# STM32F446MCY6 register map
File version: 1.0
Registers are 32-bit, access not given, reset 0x0 unless marked. A register's access mark holds for its fields unless they carry their own. Offsets are from the block's base; [hi:lo] are bit positions; {n}, {i} and the like mark numbered series; 'fields as' and 'values as' point back to an identical list.

## TIM13
Base 0x40001C00
Same registers: TIM14 0x40002000, TIM10 0x40014400, TIM11 0x40014800
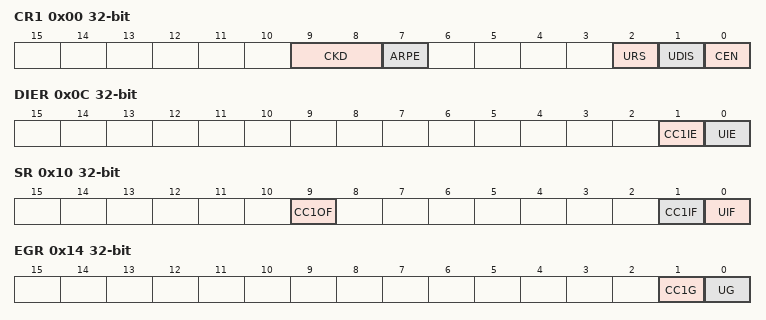
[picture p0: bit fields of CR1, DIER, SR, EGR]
0x00 CR1
  [9:8] CKD, [7] ARPE, [2] URS, [1] UDIS, [0] CEN
0x08 SMCR
0x0C DIER
  [1] CC1IE, [0] UIE
0x10 SR
  [9] CC1OF, [1] CC1IF, [0] UIF
0x14 EGR
  [1] CC1G, [0] UG
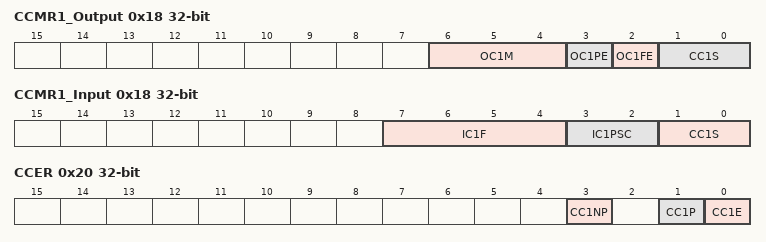
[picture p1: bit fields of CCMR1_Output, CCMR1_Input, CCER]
0x18 CCMR1_Output
  [6:4] OC1M, [3] OC1PE, [2] OC1FE, [1:0] CC1S
0x18 CCMR1_Input
  [7:4] IC1F, [3:2] IC1PSC, [1:0] CC1S
0x20 CCER
  [3] CC1NP, [1] CC1P, [0] CC1E
0x24 CNT
  [15:0] CNT
0x28 PSC
  [15:0] PSC
0x2C ARR
  [15:0] ARR
0x34 CCR1
  [15:0] CCR1
0x50 OR
  [1:0] TI1_RMP

## BKP
Base 0x40002800
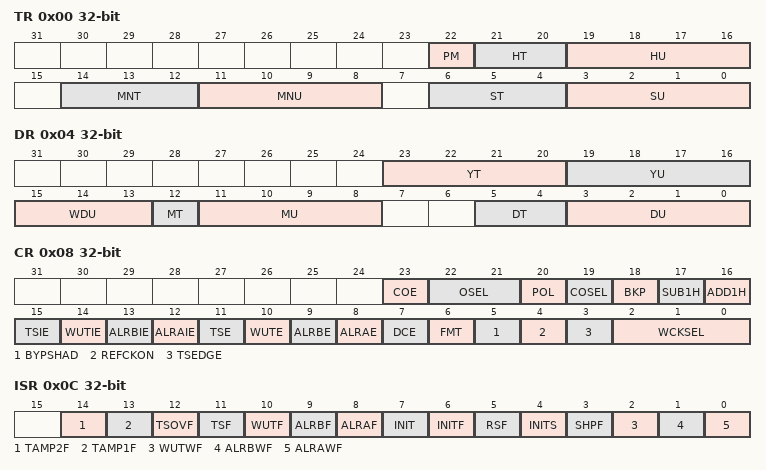
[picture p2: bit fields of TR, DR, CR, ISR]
0x00 TR
  [22] PM, [21:20] HT, [19:16] HU, [14:12] MNT, [11:8] MNU, [6:4] ST, [3:0] SU
0x04 DR
  [23:20] YT, [19:16] YU, [15:13] WDU, [12] MT, [11:8] MU, [5:4] DT, [3:0] DU
0x08 CR
  [23] COE, [22:21] OSEL, [20] POL, [19] COSEL, [18] BKP, [17] SUB1H, [16] ADD1H, [15] TSIE, [14] WUTIE, [13] ALRBIE, [12] ALRAIE, [11] TSE, [10] WUTE, [9] ALRBE, [8] ALRAE, [7] DCE, [6] FMT, [5] BYPSHAD, [4] REFCKON, [3] TSEDGE, [2:0] WCKSEL
0x0C ISR
  [14] TAMP2F, [13] TAMP1F, [12] TSOVF, [11] TSF, [10] WUTF, [9] ALRBF, [8] ALRAF, [7] INIT, [6] INITF, [5] RSF, [4] INITS, [3] SHPF, [2] WUTWF, [1] ALRBWF, [0] ALRAWF
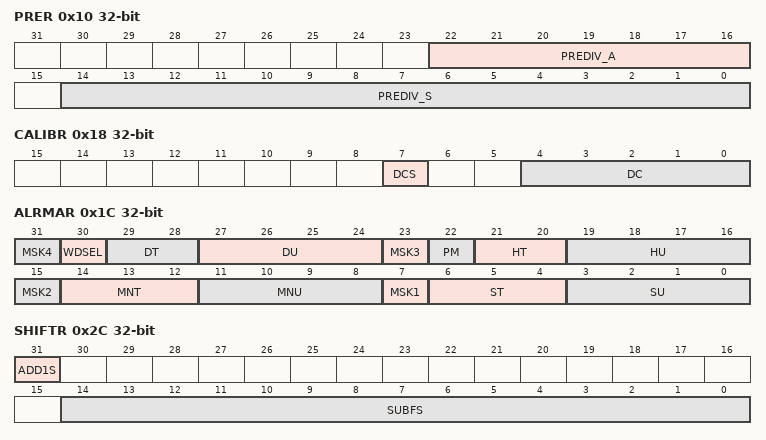
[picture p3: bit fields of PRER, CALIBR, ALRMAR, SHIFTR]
0x10 PRER
  [22:16] PREDIV_A, [14:0] PREDIV_S
0x14 WUTR
  [15:0] WUT
0x18 CALIBR
  [7] DCS, [4:0] DC
0x1C ALRMAR
  [8n-1] MSK{n} (n=1..4), [30] WDSEL, [29:28] DT, [27:24] DU, [22] PM, [21:20] HT, [19:16] HU, [14:12] MNT, [11:8] MNU, [6:4] ST, [3:0] SU
0x20 ALRMBR
  [31] MSK4, [30] WDSEL, [29:28] DT, [27:24] DU, [23] MSK3, [22] PM, [21:20] HT, [19:16] HU, [14:12] MNT, [11:8] MNU, [15:7] MSK2, [6:4] ST, [3:0] SU
0x24 WPR
  [7:0] KEY
0x28 SSR
  [15:0] SS
0x2C SHIFTR
  [31] ADD1S, [14:0] SUBFS
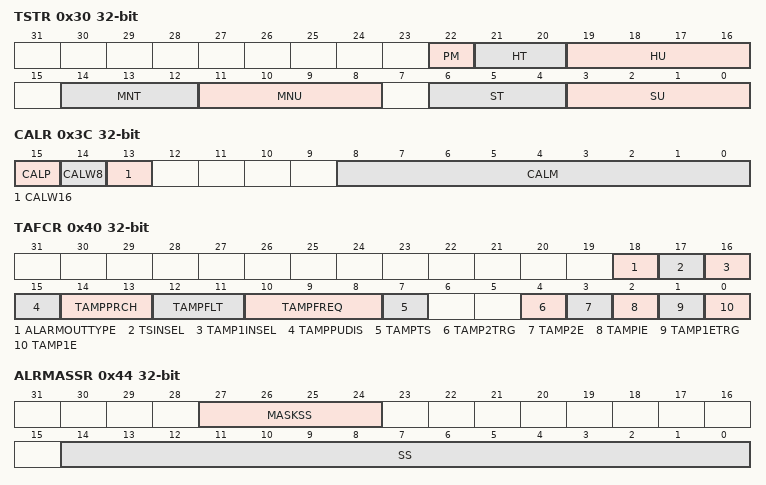
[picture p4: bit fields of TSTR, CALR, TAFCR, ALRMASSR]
0x30 TSTR
  fields as TR
0x38 TSSSR
  [15:0] SS
0x3C CALR
  [15] CALP, [14] CALW8, [13] CALW16, [8:0] CALM
0x40 TAFCR
  [18] ALARMOUTTYPE, [17] TSINSEL, [16] TAMP1INSEL, [15] TAMPPUDIS, [14:13] TAMPPRCH, [12:11] TAMPFLT, [10:8] TAMPFREQ, [7] TAMPTS, [4] TAMP2TRG, [3] TAMP2E, [2] TAMPIE, [1] TAMP1ETRG, [0] TAMP1E
0x44 ALRMASSR
  [27:24] MASKSS, [14:0] SS
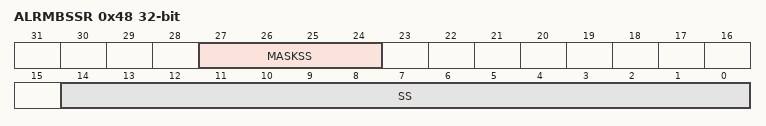
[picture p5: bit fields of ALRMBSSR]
0x48 ALRMBSSR
  [27:24] MASKSS, [14:0] SS
{0x50+4i} BKP{i}R (i=0..19)
  [31:0] BKP

## RTC
Base 0x40002800
Registers as BKP; these are added or differ:
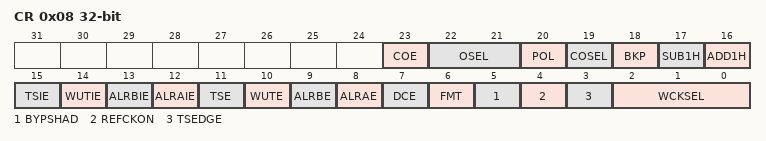
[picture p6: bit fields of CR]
0x08 CR
  fields as BKP.CR
{0x50+4i} BKP{i}R (i=0..19)
  [31:0] BKP

## WWDG
Base 0x40002C00
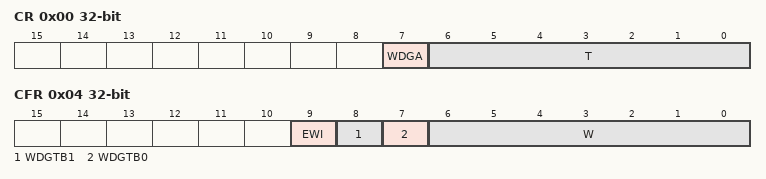
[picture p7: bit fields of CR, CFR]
0x00 CR
  [7] WDGA, [6:0] T
0x04 CFR
  [9] EWI, [8] WDGTB1, [7] WDGTB0, [6:0] W
0x08 SR
  [0] EWIF

## IWDG
Base 0x40003000
0x00 KR
  [15:0] KEY
0x04 PR
  [2:0] PR
0x08 RLR
  [11:0] RL
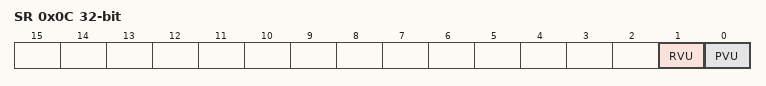
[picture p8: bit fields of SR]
0x0C SR
  [1] RVU, [0] PVU

## SPI2
Base 0x40003800
Same registers: SPI3 0x40003C00, SPI1 0x40013000, SPI4 0x40013400
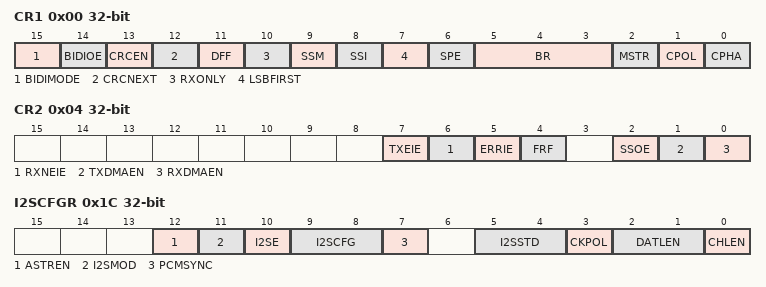
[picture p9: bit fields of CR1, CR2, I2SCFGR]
0x00 CR1
  [15] BIDIMODE, [14] BIDIOE, [13] CRCEN, [12] CRCNEXT, [11] DFF, [10] RXONLY, [9] SSM, [8] SSI, [7] LSBFIRST, [6] SPE, [5:3] BR, [2] MSTR, [1] CPOL, [0] CPHA
0x04 CR2
  [7] TXEIE, [6] RXNEIE, [5] ERRIE, [4] FRF, [2] SSOE, [1] TXDMAEN, [0] RXDMAEN
0x08 SR
0x0C DR
  [15:0] DR
0x10 CRCPR
  [15:0] CRCPOLY
0x14 RXCRCR
  [15:0] RxCRC
0x18 TXCRCR
  [15:0] TxCRC
0x1C I2SCFGR
  [12] ASTREN, [11] I2SMOD, [10] I2SE, [9:8] I2SCFG, [7] PCMSYNC, [5:4] I2SSTD, [3] CKPOL, [2:1] DATLEN, [0] CHLEN
0x20 I2SPR

## SPDIFRX
Base 0x40004000
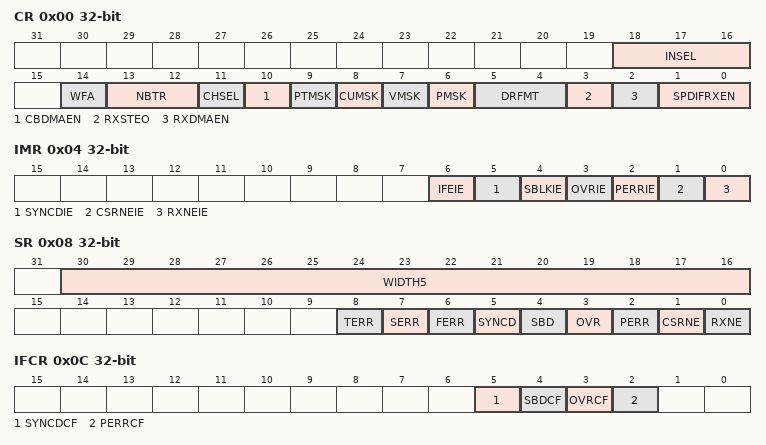
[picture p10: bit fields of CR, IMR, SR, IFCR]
0x00 CR
  [18:16] INSEL, [14] WFA, [13:12] NBTR, [11] CHSEL, [10] CBDMAEN, [9] PTMSK, [8] CUMSK, [7] VMSK, [6] PMSK, [5:4] DRFMT, [3] RXSTEO, [2] RXDMAEN, [1:0] SPDIFRXEN
0x04 IMR
  [6] IFEIE, [5] SYNCDIE, [4] SBLKIE, [3] OVRIE, [2] PERRIE, [1] CSRNEIE, [0] RXNEIE
0x08 SR
  [30:16] WIDTH5, [8] TERR, [7] SERR, [6] FERR, [5] SYNCD, [4] SBD, [3] OVR, [2] PERR, [1] CSRNE, [0] RXNE
0x0C IFCR
  [5] SYNCDCF, [4] SBDCF, [3] OVRCF, [2] PERRCF
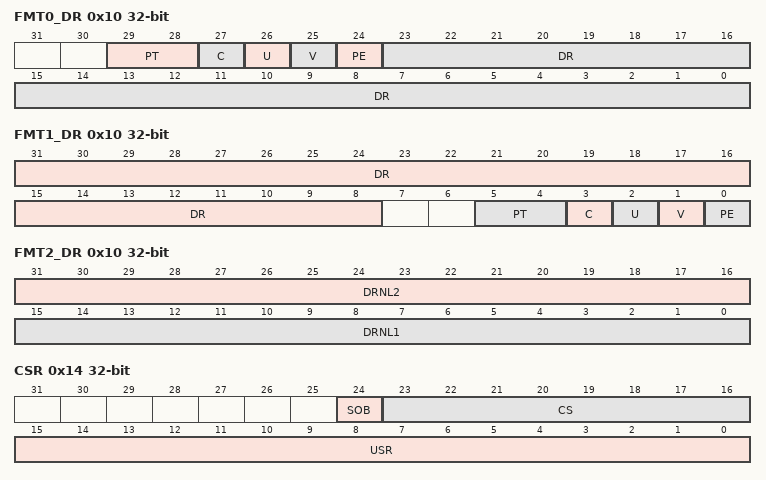
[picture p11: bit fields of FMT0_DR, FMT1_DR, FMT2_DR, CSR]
0x10 FMT0_DR
  [29:28] PT, [27] C, [26] U, [25] V, [24] PE, [23:0] DR
0x10 FMT1_DR
  [31:8] DR, [5:4] PT, [3] C, [2] U, [1] V, [0] PE
0x10 FMT2_DR
  [31:16] DRNL2, [15:0] DRNL1
0x14 CSR
  [24] SOB, [23:16] CS, [15:0] USR
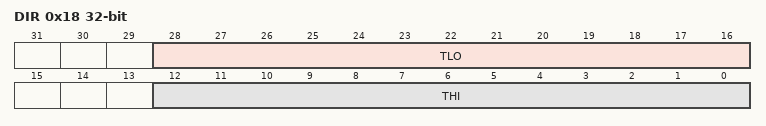
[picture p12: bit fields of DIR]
0x18 DIR
  [28:16] TLO, [12:0] THI
